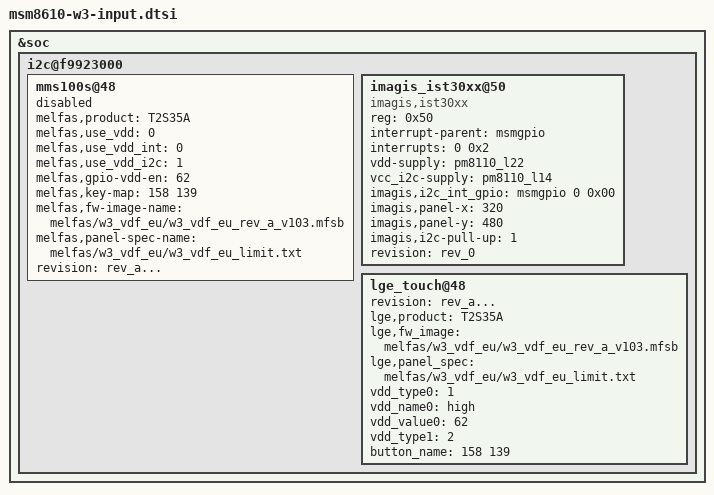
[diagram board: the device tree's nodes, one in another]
/* Copyright (c) 2012, Code Aurora Forum. All rights reserved.
 *
 * This program is free software; you can redistribute it and/or modify
 * it under the terms of the GNU General Public License version 2 and
 * only version 2 as published by the Free Software Foundation.
 *
 * This program is distributed in the hope that it will be useful,
 * but WITHOUT ANY WARRANTY; without even the implied warranty of
 * MERCHANTABILITY or FITNESS FOR A PARTICULAR PURPOSE.  See the
 * GNU General Public License for more details.
 */

&soc {
	i2c@f9923000{
		mms100s@48 {
			melfas,product = "T2S35A";
			melfas,use_vdd = <0>;
			melfas,use_vdd_int = <0>;
			melfas,use_vdd_i2c = <1>;
			melfas,gpio-vdd-en = <62>;
			melfas,key-map = <158 139>;
			melfas,fw-image-name = "melfas/w3_vdf_eu/w3_vdf_eu_rev_a_v103.mfsb";
			melfas,panel-spec-name = "melfas/w3_vdf_eu/w3_vdf_eu_limit.txt";
			status = "disable";
			revision = "rev_a...";
		};

		imagis_ist30xx@50 {
			compatible = "imagis,ist30xx";
			reg = <0x50>;
			interrupt-parent = <&msmgpio>;
			interrupts = <0 0x2>;
			vdd-supply = <&pm8110_l22>;
			vcc_i2c-supply = <&pm8110_l14>;
			imagis,i2c_int_gpio = <&msmgpio 0 0x00>;
			imagis,panel-x = <320>;
			imagis,panel-y = <480>;
			imagis,i2c-pull-up = <1>;
			status = "ok";
			revision = "rev_0";
		};
		lge_touch@48 {
			revision = "rev_a...";
			status = "ok";
			lge,product = "T2S35A";
			lge,fw_image = "melfas/w3_vdf_eu/w3_vdf_eu_rev_a_v103.mfsb";
			lge,panel_spec = "melfas/w3_vdf_eu/w3_vdf_eu_limit.txt";
			vdd_type0 = <1>;
			vdd_name0 = "high";
			vdd_value0 = <62>;
			vdd_type1 = <2>;
			button_name = <158 139>;
		};
	};
};
